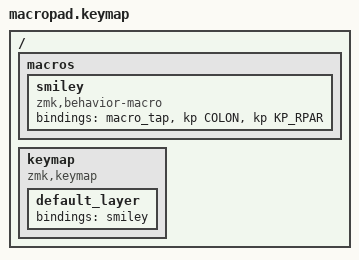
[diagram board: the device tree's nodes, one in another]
#include <behaviors.dtsi>
#include <dt-bindings/zmk/keys.h>
#include <dt-bindings/zmk/bt.h>

/ {
    macros {
        smiley: smiley {
            compatible = "zmk,behavior-macro";
            #binding-cells = <0>;
	    bindings = <&macro_tap &kp COLON &kp KP_RPAR>;
	};
    };

    keymap {
        compatible = "zmk,keymap";

	default_layer {
            bindings = <
	        &smiley
	    >;
	};
    };
};
